# Z20K14xM register map
Vendor: Zhixin Semiconductor; Series: Z20K14xM; File version: 0.1.0
reference description for MCU with ARM 32-bit Cortex-M4F Microcontroller
CPU: CM4 r0p1, little endian, no MPU, FPU, 4 interrupt priority bits
Registers are 32-bit, read-write, reset 0x0 unless marked. A register's access mark holds for its fields unless they carry their own. Offsets are from the block's base; lines under a group give offsets from that group; [hi:lo] are bit positions; {n}, {i} and the like mark numbered series; 'fields as' and 'values as' point back to an identical list; <NAME> marks a mode.

## Memory map
0x40008000 DMA size 0x1000
0x40009000 DMUX size 0x1000
0x4000A000 SMPU size 0x1000
0x4000B000 EIRU size 0x1000
0x4000C000 TIM0 size 0x1000
0x4000D000 TIM1 size 0x1000
0x4000E000 MCPWM0 size 0x1000
0x4000F000 TDG0 size 0x1000
0x40018000 TIM2 size 0x1000
0x40019000 TIM3 size 0x1000
0x4001A000 MCPWM1 size 0x1000
0x4001B000 TDG1 size 0x1000
0x40020000 FLASHC size 0x1000
0x40024000 CAN0 size 0x1000
0x40025000 CAN1 size 0x1000
0x40027000 ADC1 size 0x1000
0x4002C000 SPI0 size 0x1000
0x4002D000 SPI1 size 0x1000
0x40030000 SPI2 size 0x1000
0x40031000 SPI3 size 0x1000
0x40032000 CRC size 0x1000
0x40034000 TRNG size 0x1000
0x40038000 CAN2 size 0x1000
0x40039000 CAN3 size 0x1000
0x4003B000 ADC0 size 0x1000
0x4003E000 CMU0 size 0x1000
0x40040000 STIM size 0x1000
0x40042000 CMU1 size 0x1000
0x40043000 CMU2 size 0x1000
0x40044000 CAN4 size 0x1000
0x40045000 CAN5 size 0x1000
0x40048000 SCM size 0x1000
0x40049000 PORT size 0x1000
0x40052000 WDOG size 0x1000
0x40054000 I2S0 size 0x1000
0x40055000 I2S1 size 0x1000
0x40056000 CAN6 size 0x1000
0x40057000 CAN7 size 0x1000
0x40058000 I2C1 size 0x1000
0x40061000 EWDT size 0x1000
0x40063000 TMU size 0x1000
0x40064000 SCC size 0x1000
0x40065000 PARCC size 0xD4
0x40066000 I2C0 size 0x1000
0x4006A000 UART0 size 0x1000
0x4006B000 UART1 size 0x1000
0x4006C000 UART2 size 0x1000
0x40070000 UART3 size 0x1000
0x40071000 UART4 size 0x1000
0x40072000 UART5 size 0x1000
0x40073000 CMP size 0x1000
0x40079000 RTC size 0x1000
0x4007C000 REGFILE size 0x1000
0x4007D000 PMU size 0x1000
0x4007E000 SRMC size 0x1000
0x4007F000 SERU size 0x1000
0x400FF000 GPIO size 0x1000
0x400332000 AES size 0x1000

## Further device data
ExampleStackSize=1024, ExampleHeapSize=512, MaxInterrupts=50

## DMUX
Base 0x40009000
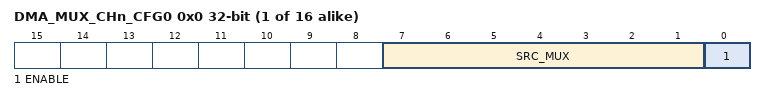
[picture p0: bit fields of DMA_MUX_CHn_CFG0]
{0x0+4i} DMA_MUX_CHn_CFG{i} (i=0..15) — DMA Channel Mux Configuration Register(DMA_MUX_CHn_CFG)
  [7:1] SRC_MUX — DMA MUX Source
  [0] ENABLE — DMA MUX Enable

## EIRU
Base 0x4000B000
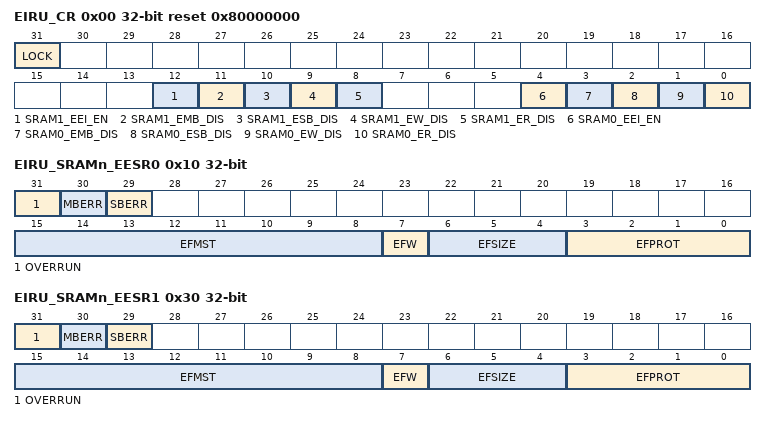
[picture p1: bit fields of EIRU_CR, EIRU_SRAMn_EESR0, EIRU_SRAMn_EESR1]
0x00 EIRU_CR ro reset 0x80000000 — EIRU control register(EIRU_CR)
  [31] LOCK — Global EIRU Lock Bit
  [12] SRAM1_EEI_EN — SRAM1 ECC Error Injection Enable
  [11] SRAM1_EMB_DIS — SRAM1 ECC Multi Bit Disable
  [10] SRAM1_ESB_DIS — SRAM1 ECC Single Bit Disable
  [9] SRAM1_EW_DIS — SRAM1 ECC Write Disable
  [8] SRAM1_ER_DIS — SRAM1 ECC Read Disable
  [4] SRAM0_EEI_EN — SRAM0 ECC Error Injection Enable
  [3] SRAM0_EMB_DIS — SRAM0 ECC Multi Bit Disable
  [2] SRAM0_ESB_DIS — SRAM0 ECC Single Bit Disable
  [1] SRAM0_EW_DIS — SRAM0 ECC Write Disable
  [0] SRAM0_ER_DIS — SRAM0 ECC Read Disable
0x04 EIRU_EEIADDR — EIRU ECC Error Injection Address(EIRU_EEIADDR)
  [31:2] EEIADDR — ECC Error Injection Address
0x10 EIRU_SRAMn_EESR0 ro — EIRU SRAM n ECC Error Status Register(EIRU_SRAMn_EESR)
  [31] OVERRUN — ECC Error Overrun
  [30] MBERR — ECC Multi-bit Error
  [29] SBERR — ECC Single-bit Error
  [15:8] EFMST — ECC Fault Master
  [7] EFW — ECC Fault Write
  [6:4] EFSIZE — ECC Fault HSIZE
  [3:0] EFPROT — ECC Fault HPROT
0x14 EIRU_SRAMn_FADDR0 ro — EIRU SRAM n ECC Fault Address Register(EIRU_SRAMn_FADDR)
  [31:0] EFADDR — ECC Fault Address
0x18 EIRU_SRAMn_FDATA0 ro — EIRU SRAM n ECC Fault Data Register(EIRU_SRAMn_FDATA)
  [31:0] EFDATA — ECC Fault Data
0x1C EIRU_SRAMn_ECCMASK0 — EIRU SRAM n ECC Check Bit MASK(EIRU_SRAMn_ECCMASK)
  [6:0] ECCMASK — ECC Bit Mask
0x20 EIRU_SRAMn_DATAMASK0 — EIRU SRAM n DATA Bit MASK(EIRU_CHn_DATAMASK)
  [31:0] DATAMASK — Data bit mask
0x30 EIRU_SRAMn_EESR1 ro — EIRU SRAM n ECC Error Status Register(EIRU_SRAMn_EESR)
  fields as EIRU_SRAMn_EESR0
0x34 EIRU_SRAMn_FADDR1 ro — EIRU SRAM n ECC Fault Address Register(EIRU_SRAMn_FADDR)
  [31:0] EFADDR — ECC Fault Address
0x38 EIRU_SRAMn_FDATA1 ro — EIRU SRAM n ECC Fault Data Register(EIRU_SRAMn_FDATA)
  [31:0] EFDATA — ECC Fault Data
0x3C EIRU_SRAMn_ECCMASK1 — EIRU SRAM n ECC Check Bit MASK(EIRU_SRAMn_ECCMASK)
  [6:0] ECCMASK — ECC Bit Mask
0x40 EIRU_SRAMn_DATAMASK1 — EIRU SRAM n DATA Bit MASK(EIRU_CHn_DATAMASK)
  [31:0] DATAMASK — Data bit mask

## Licence text in the file
Copyright (c) 2022, Zhixin Semiconductor
